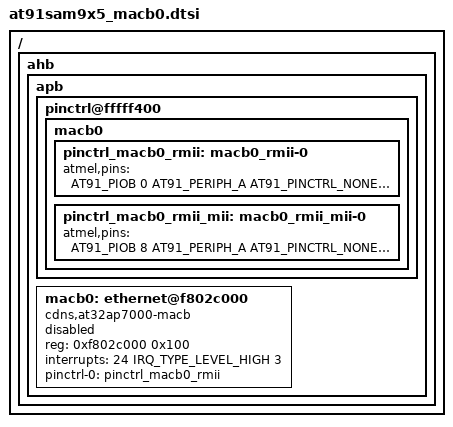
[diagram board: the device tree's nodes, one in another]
/*
 * at91sam9x5_macb0.dtsi - Device Tree Include file for AT91SAM9x5 SoC with 1
 * Ethernet interface.
 *
 * Copyright (C) 2013 Boris BREZILLON <b.brezillon@overkiz.com>
 *
 * Licensed under GPLv2.
 */

#include <dt-bindings/pinctrl/at91.h>
#include <dt-bindings/interrupt-controller/irq.h>

/ {
	ahb {
		apb {
			pinctrl@fffff400 {
				macb0 {
					pinctrl_macb0_rmii: macb0_rmii-0 {
						atmel,pins =
							<AT91_PIOB 0 AT91_PERIPH_A AT91_PINCTRL_NONE	/* PB0 periph A */
							 AT91_PIOB 1 AT91_PERIPH_A AT91_PINCTRL_NONE	/* PB1 periph A */
							 AT91_PIOB 2 AT91_PERIPH_A AT91_PINCTRL_NONE	/* PB2 periph A */
							 AT91_PIOB 3 AT91_PERIPH_A AT91_PINCTRL_NONE	/* PB3 periph A */
							 AT91_PIOB 4 AT91_PERIPH_A AT91_PINCTRL_NONE	/* PB4 periph A */
							 AT91_PIOB 5 AT91_PERIPH_A AT91_PINCTRL_NONE	/* PB5 periph A */
							 AT91_PIOB 6 AT91_PERIPH_A AT91_PINCTRL_NONE	/* PB6 periph A */
							 AT91_PIOB 7 AT91_PERIPH_A AT91_PINCTRL_NONE	/* PB7 periph A */
							 AT91_PIOB 9 AT91_PERIPH_A AT91_PINCTRL_NONE	/* PB9 periph A */
							 AT91_PIOB 10 AT91_PERIPH_A AT91_PINCTRL_NONE>;	/* PB10 periph A */
					};

					pinctrl_macb0_rmii_mii: macb0_rmii_mii-0 {
						atmel,pins =
							<AT91_PIOB 8 AT91_PERIPH_A AT91_PINCTRL_NONE	/* PB8 periph A */
							 AT91_PIOB 11 AT91_PERIPH_A AT91_PINCTRL_NONE	/* PB11 periph A */
							 AT91_PIOB 12 AT91_PERIPH_A AT91_PINCTRL_NONE	/* PB12 periph A */
							 AT91_PIOB 13 AT91_PERIPH_A AT91_PINCTRL_NONE	/* PB13 periph A */
							 AT91_PIOB 14 AT91_PERIPH_A AT91_PINCTRL_NONE	/* PB14 periph A */
							 AT91_PIOB 15 AT91_PERIPH_A AT91_PINCTRL_NONE	/* PB15 periph A */
							 AT91_PIOB 16 AT91_PERIPH_A AT91_PINCTRL_NONE	/* PB16 periph A */
							 AT91_PIOB 17 AT91_PERIPH_A AT91_PINCTRL_NONE>;	/* PB17 periph A */
					};
				};
			};

			macb0: ethernet@f802c000 {
				compatible = "cdns,at32ap7000-macb", "cdns,macb";
				reg = <0xf802c000 0x100>;
				interrupts = <24 IRQ_TYPE_LEVEL_HIGH 3>;
				pinctrl-names = "default";
				pinctrl-0 = <&pinctrl_macb0_rmii>;
				status = "disabled";
			};
		};
	};
};
